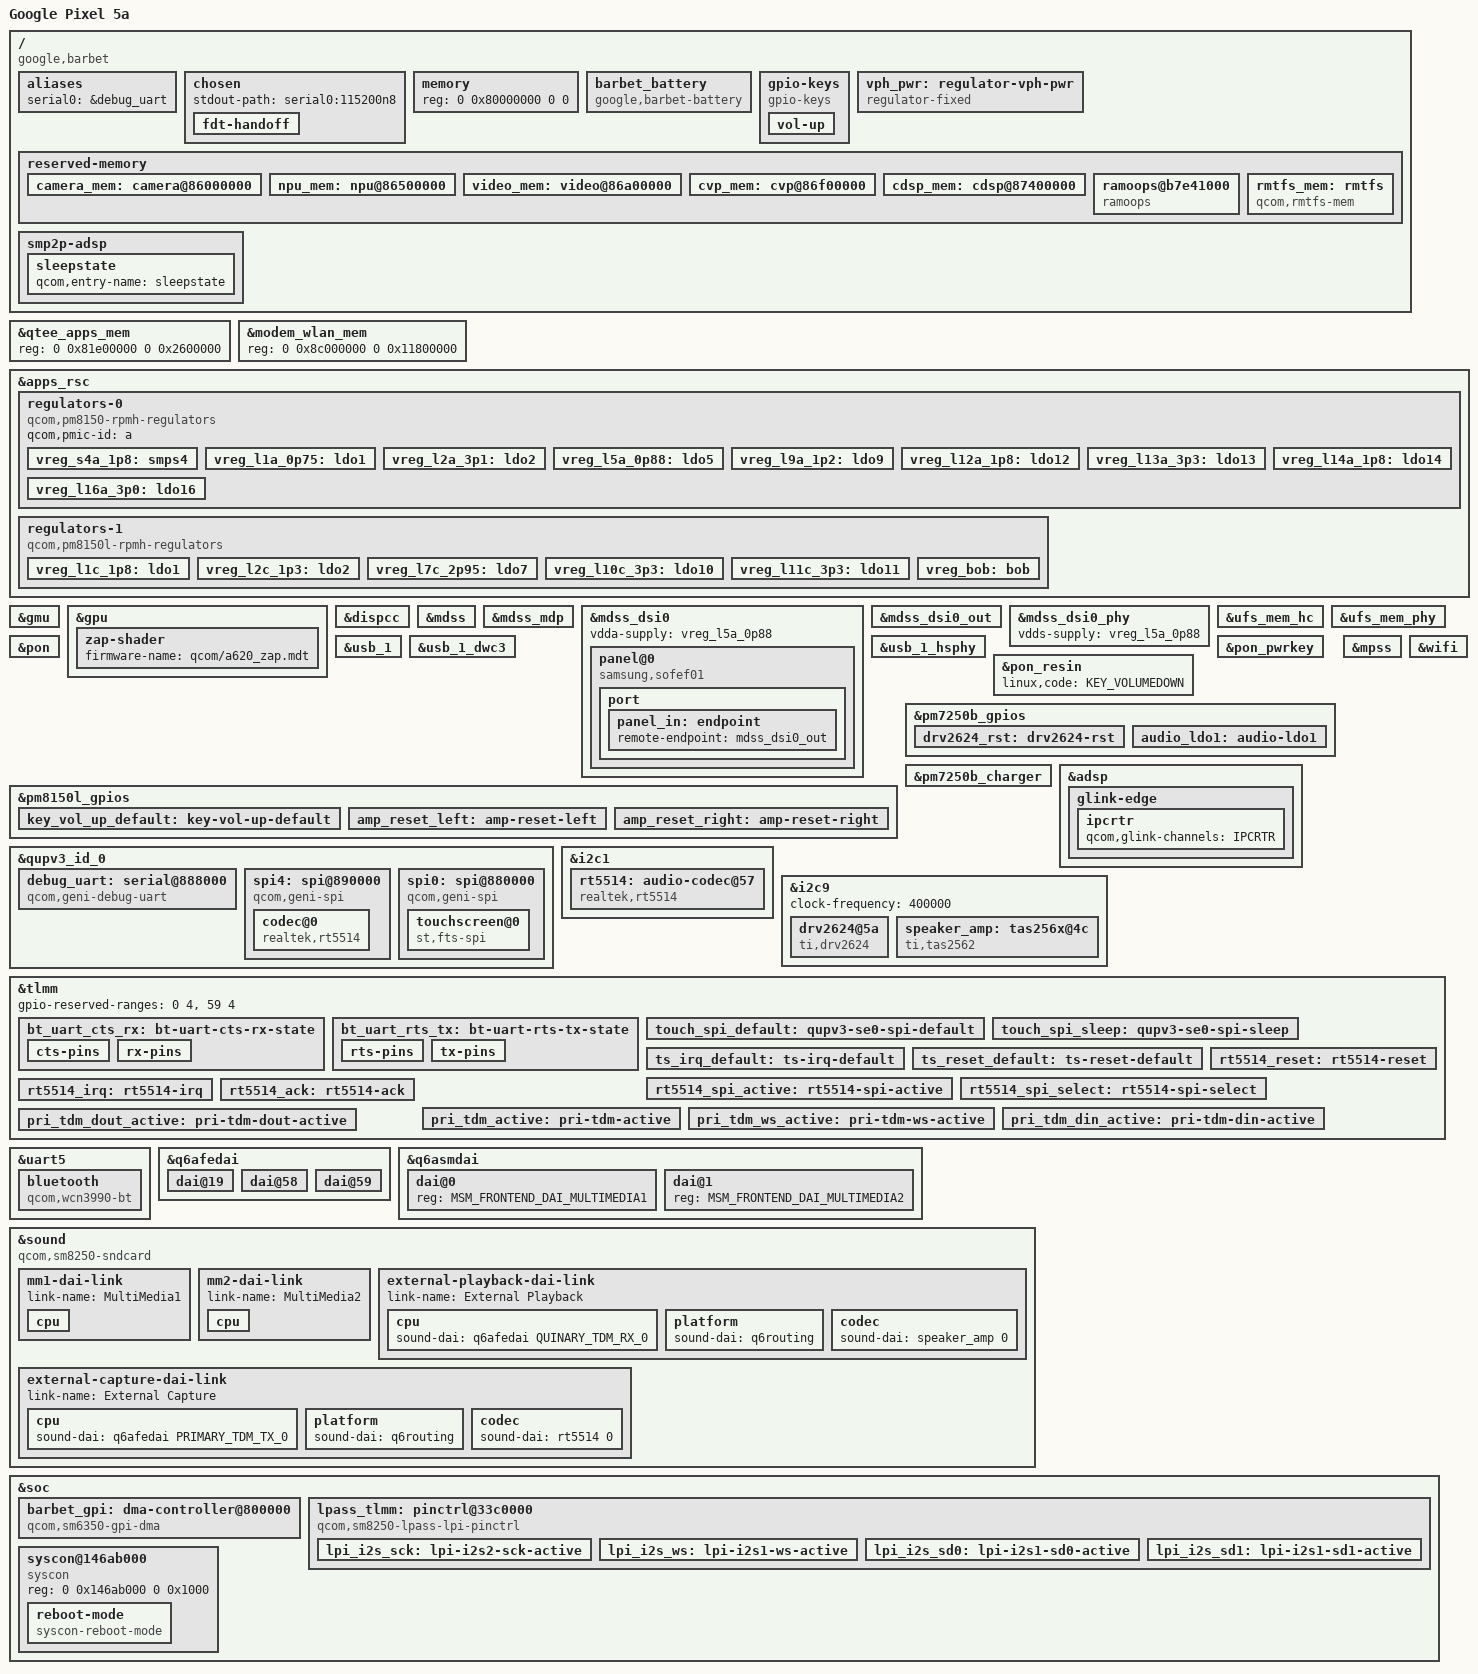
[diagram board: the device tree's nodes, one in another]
// SPDX-License-Identifier: BSD-3-Clause
/*
 * Google Pixel 5a (barbet).
 *
 * Family layout and regulator descriptions derive from the avicii-mainline
 * sm7250-oneplus-avicii.dts source (Sreeshankar K's SM7250 work).
 * Board wiring and reserved-memory sizes were checked against Google's
 * redbull kernel sources: lito-barbet.dtsi, lito-barbet-audio.dtsi and
 * lito-barbet-haptics.dtsi. The compiled bring-up tree is comparison evidence,
 * not an included or decompiled source tree.
 */

/dts-v1/;

#include <dt-bindings/gpio/gpio.h>
#include <dt-bindings/input/input.h>
#include <dt-bindings/pinctrl/qcom,pmic-gpio.h>
#include <dt-bindings/regulator/qcom,rpmh-regulator.h>
#include <dt-bindings/sound/qcom,q6asm.h>

#define PM7250B_SID 2
#define PM7250B_SID1 3

#include "sm7250.dtsi"
#include "pm8150.dtsi"
#include "pm8150l.dtsi"
#include "pm7250b.dtsi"

/* Replace the family defaults with Google's carveout addresses. */
/delete-node/ &camera_mem;
/delete-node/ &npu_mem;
/delete-node/ &video_mem;
/delete-node/ &cvp_mem;
/delete-node/ &cdsp_mem;

/ {
	model = "Google Pixel 5a";
	compatible = "google,barbet", "qcom,sm7250", "qcom,lito";
	chassis-type = "handset";
	qcom,msm-id = <0x190 0x10000 0x1b8 0x10000>;
	qcom,board-id = <0 0>;

	aliases {
		serial0 = &debug_uart;
	};

	chosen {
		stdout-path = "serial0:115200n8";

		/*
		 * Hand the bootloader's own Barbet tree to the kernel's
		 * matching one, and keep the initramfs the bootloader loaded.
		 */
		fdt-handoff {
			stock-compatible = "google,barbet-sm7250";
			stock-model = "Google Inc. MSM sm7250 v2 Barbet MP";
			keep-initrd;
		};
	};

	/*
	 * The Pixel bootloader patches /memory (without a unit address), so
	 * keep the stock node shape for it to fill in the real DRAM size.
	 */
	memory {
		device_type = "memory";
		reg = <0 0x80000000 0 0>;
	};

	barbet_battery {
		compatible = "google,barbet-battery";
		io-channels = <&pm7250b_adc 0x84>;
		voltage-min-microvolt = <3200000>;
		voltage-max-microvolt = <4350000>;
	};

	gpio-keys {
		compatible = "gpio-keys";
		label = "gpio-keys";
		pinctrl-names = "default";
		pinctrl-0 = <&key_vol_up_default>;

		vol-up {
			label = "Volume Up";
			gpios = <&pm8150l_gpios 5 GPIO_ACTIVE_LOW>;
			linux,code = <KEY_VOLUMEUP>;
			debounce-interval = <15>;
			wakeup-source;
		};
	};

	vph_pwr: regulator-vph-pwr {
		compatible = "regulator-fixed";
		regulator-name = "vph_pwr";
		regulator-min-microvolt = <4200000>;
		regulator-max-microvolt = <4200000>;
		regulator-always-on;
	};

	reserved-memory {
		camera_mem: camera@86000000 {
			reg = <0 0x86000000 0 0x500000>;
			no-map;
		};

		npu_mem: npu@86500000 {
			reg = <0 0x86500000 0 0x500000>;
			no-map;
		};

		video_mem: video@86a00000 {
			reg = <0 0x86a00000 0 0x500000>;
			no-map;
		};

		cvp_mem: cvp@86f00000 {
			reg = <0 0x86f00000 0 0x500000>;
			no-map;
		};

		cdsp_mem: cdsp@87400000 {
			reg = <0 0x87400000 0 0x1e00000>;
			no-map;
		};

		ramoops@b7e41000 {
			compatible = "ramoops";
			reg = <0 0xb7e41000 0 0x400000>;
			record-size = <0x20000>;
			console-size = <0x100000>;
			pmsg-size = <0x80000>;
			no-map;
		};

		rmtfs_mem: rmtfs {
			compatible = "qcom,rmtfs-mem";
			size = <0 0x280000>;
			alloc-ranges = <0 0xa4000000 0 0x10000000>;
			alignment = <0 0x400000>;
			no-map;
			qcom,client-id = <1>;
			qcom,vmid = <15>;
		};
	};

	smp2p-adsp {
		sleepstate {
			qcom,entry-name = "sleepstate";
			#qcom,smem-state-cells = <1>;
		};
	};
};

/* Barbet's firmware carveouts differ from the OnePlus memory map. */
&qtee_apps_mem {
	reg = <0 0x81e00000 0 0x2600000>;
};

&modem_wlan_mem {
	reg = <0 0x8c000000 0 0x11800000>;
};

&apps_rsc {
	regulators-0 {
		compatible = "qcom,pm8150-rpmh-regulators";
		qcom,pmic-id = "a";

		vreg_s4a_1p8: smps4 {
			regulator-name = "vreg_s4a_1p8";
			regulator-min-microvolt = <1800000>;
			regulator-max-microvolt = <1800000>;
			regulator-boot-on;
			regulator-always-on;
		};

		vreg_l1a_0p75: ldo1 {
			regulator-name = "vreg_l1a_0p75";
			regulator-min-microvolt = <752000>;
			regulator-max-microvolt = <752000>;
			regulator-initial-mode = <RPMH_REGULATOR_MODE_HPM>;
			regulator-boot-on;
			regulator-always-on;
		};

		vreg_l2a_3p1: ldo2 {
			regulator-name = "vreg_l2a_3p1";
			regulator-min-microvolt = <3072000>;
			regulator-max-microvolt = <3072000>;
			regulator-initial-mode = <RPMH_REGULATOR_MODE_HPM>;
			regulator-boot-on;
			regulator-always-on;
		};

		vreg_l5a_0p88: ldo5 {
			regulator-name = "vreg_l5a_0p88";
			regulator-min-microvolt = <880000>;
			regulator-max-microvolt = <880000>;
			regulator-initial-mode = <RPMH_REGULATOR_MODE_HPM>;
			regulator-boot-on;
			regulator-always-on;
		};

		vreg_l9a_1p2: ldo9 {
			regulator-name = "vreg_l9a_1p2";
			regulator-min-microvolt = <1200000>;
			regulator-max-microvolt = <1200000>;
			regulator-initial-mode = <RPMH_REGULATOR_MODE_HPM>;
			regulator-boot-on;
			regulator-always-on;
		};

		vreg_l12a_1p8: ldo12 {
			regulator-name = "vreg_l12a_1p8";
			regulator-min-microvolt = <1800000>;
			regulator-max-microvolt = <1800000>;
			regulator-initial-mode = <RPMH_REGULATOR_MODE_HPM>;
			regulator-boot-on;
			regulator-always-on;
		};

		vreg_l13a_3p3: ldo13 {
			regulator-name = "vreg_l13a_3p3";
			regulator-min-microvolt = <3304000>;
			regulator-max-microvolt = <3304000>;
			regulator-initial-mode = <RPMH_REGULATOR_MODE_HPM>;
			regulator-boot-on;
			regulator-always-on;
		};

		vreg_l14a_1p8: ldo14 {
			regulator-name = "vreg_l14a_1p8";
			regulator-min-microvolt = <1800000>;
			regulator-max-microvolt = <1800000>;
			regulator-initial-mode = <RPMH_REGULATOR_MODE_HPM>;
			regulator-boot-on;
			regulator-always-on;
		};

		vreg_l16a_3p0: ldo16 {
			regulator-name = "vreg_l16a_3p0";
			regulator-min-microvolt = <3000000>;
			regulator-max-microvolt = <3000000>;
			regulator-initial-mode = <RPMH_REGULATOR_MODE_HPM>;
			regulator-boot-on;
			regulator-always-on;
		};
	};

	regulators-1 {
		compatible = "qcom,pm8150l-rpmh-regulators";
		qcom,pmic-id = "c";
		vdd-bob-supply = <&vph_pwr>;

		vreg_l1c_1p8: ldo1 {
			regulator-name = "vreg_l1c_1p8";
			regulator-min-microvolt = <1800000>;
			regulator-max-microvolt = <1800000>;
			regulator-initial-mode = <RPMH_REGULATOR_MODE_HPM>;
			regulator-boot-on;
			regulator-always-on;
		};

		vreg_l2c_1p3: ldo2 {
			regulator-name = "vreg_l2c_1p3";
			regulator-min-microvolt = <1304000>;
			regulator-max-microvolt = <1304000>;
			regulator-initial-mode = <RPMH_REGULATOR_MODE_HPM>;
		};

		vreg_l7c_2p95: ldo7 {
			regulator-name = "vreg_l7c_2p95";
			regulator-min-microvolt = <2950000>;
			regulator-max-microvolt = <2960000>;
			regulator-initial-mode = <RPMH_REGULATOR_MODE_HPM>;
			regulator-boot-on;
			regulator-always-on;
		};

		vreg_l10c_3p3: ldo10 {
			regulator-name = "vreg_l10c_3p3";
			regulator-min-microvolt = <3312000>;
			regulator-max-microvolt = <3312000>;
			regulator-initial-mode = <RPMH_REGULATOR_MODE_HPM>;
		};

		vreg_l11c_3p3: ldo11 {
			regulator-name = "vreg_l11c_3p3";
			regulator-min-microvolt = <3312000>;
			regulator-max-microvolt = <3312000>;
			regulator-initial-mode = <RPMH_REGULATOR_MODE_HPM>;
		};

		vreg_bob: bob {
			regulator-name = "vreg_bob";
			regulator-min-microvolt = <3008000>;
			regulator-max-microvolt = <4000000>;
			regulator-initial-mode = <RPMH_REGULATOR_MODE_AUTO>;
			regulator-boot-on;
		};
	};
};

&gmu {
	status = "okay";
};

&gpu {
	status = "okay";
	zap-shader {
		firmware-name = "qcom/a620_zap.mdt";
	};
};

&dispcc {
	status = "okay";
};

&mdss {
	status = "okay";
};

&mdss_mdp {
	status = "okay";
};

&mdss_dsi0 {
	vdda-supply = <&vreg_l5a_0p88>;
	status = "okay";

	panel@0 {
		compatible = "samsung,sofef01";
		reg = <0>;
		vddio-supply = <&vreg_l1c_1p8>;
		vci-supply = <&vreg_l16a_3p0>;
		poc-supply = <&vreg_l16a_3p0>;
		reset-gpios = <&pm8150l_gpios 8 GPIO_ACTIVE_LOW>;

		port {
			panel_in: endpoint {
				remote-endpoint = <&mdss_dsi0_out>;
			};
		};
	};
};

&mdss_dsi0_out {
	remote-endpoint = <&panel_in>;
	data-lanes = <0 1 2 3>;
};

&mdss_dsi0_phy {
	vdds-supply = <&vreg_l5a_0p88>;
	status = "okay";
};

&ufs_mem_hc {
	vcc-supply = <&vreg_l7c_2p95>;
	vcc-max-microamp = <800000>;
	vccq2-supply = <&vreg_s4a_1p8>;
	vccq2-max-microamp = <800000>;
	status = "okay";
};

&ufs_mem_phy {
	vdda-phy-supply = <&vreg_l5a_0p88>;
	vdda-pll-supply = <&vreg_l9a_1p2>;
	status = "okay";
};

&usb_1 {
	status = "okay";
};

&usb_1_dwc3 {
	dr_mode = "peripheral";
	maximum-speed = "high-speed";
};

&usb_1_hsphy {
	vdda-pll-supply = <&vreg_l5a_0p88>;
	vdda18-supply = <&vreg_l12a_1p8>;
	vdda33-supply = <&vreg_l2a_3p1>;
	status = "okay";
};

&pon {
	mode-normal = <0>;
	mode-bootloader = <2>;
	mode-recovery = <1>;
};

&pon_pwrkey {
	status = "okay";
};

&pon_resin {
	linux,code = <KEY_VOLUMEDOWN>;
	status = "okay";
};

&pm8150l_gpios {
	key_vol_up_default: key-vol-up-default {
		pins = "gpio5";
		function = "normal";
		input-enable;
		bias-pull-up;
		power-source = <0>;
	};

	amp_reset_left: amp-reset-left {
		pins = "gpio11";
		function = "normal";
		power-source = <1>;
		qcom,drive-strength = <PMIC_GPIO_STRENGTH_MED>;
		bias-disable;
		output-high;
	};

	amp_reset_right: amp-reset-right {
		pins = "gpio10";
		function = "normal";
		power-source = <1>;
		qcom,drive-strength = <PMIC_GPIO_STRENGTH_MED>;
		bias-disable;
		output-high;
	};
};

&pm7250b_gpios {
	drv2624_rst: drv2624-rst {
		pins = "gpio1";
		output-low;
	};

	audio_ldo1: audio-ldo1 {
		pins = "gpio6";
		function = "normal";
		power-source = <1>;
		qcom,drive-strength = <PMIC_GPIO_STRENGTH_MED>;
		output-high;
	};
};

&pm7250b_charger {
	status = "okay";
};

&adsp {
	firmware-name = "qcom/sm7250/google/barbet/adsp.mdt";
	status = "okay";

	glink-edge {
		ipcrtr {
			qcom,glink-channels = "IPCRTR";
		};
	};
};

&mpss {
	firmware-name = "qcom/sm7250/google/barbet/modem.mdt";
	status = "okay";
};

&wifi {
	vdd-0.8-cx-mx-supply = <&vreg_l1a_0p75>;
	vdd-1.8-xo-supply = <&vreg_l14a_1p8>;
	vdd-1.3-rfa-supply = <&vreg_l2c_1p3>;
	vdd-3.3-ch0-supply = <&vreg_l10c_3p3>;
	vdd-3.3-ch1-supply = <&vreg_l11c_3p3>;
	firmware-name = "barbet";
	status = "okay";
};

&qupv3_id_0 {
	status = "okay";

	debug_uart: serial@888000 {
		compatible = "qcom,geni-debug-uart";
		reg = <0 0x888000 0 0x4000>;
		clock-names = "se";
		clocks = <&gcc GCC_QUPV3_WRAP0_S2_CLK>;
		interrupts = <GIC_SPI 603 IRQ_TYPE_LEVEL_HIGH>;
		pinctrl-names = "default";
		pinctrl-0 = <&qup_uart2_default>;
		interconnects = <&qup_virt MASTER_QUP_CORE_0 QCOM_ICC_TAG_ALWAYS
				 &qup_virt SLAVE_QUP_CORE_0 QCOM_ICC_TAG_ALWAYS>,
			       <&gem_noc MASTER_AMPSS_M0 QCOM_ICC_TAG_ACTIVE_ONLY
				 &config_noc SLAVE_QUP_0 QCOM_ICC_TAG_ACTIVE_ONLY>;
		interconnect-names = "qup-core", "qup-config";
		status = "okay";
	};

	spi4: spi@890000 {
		compatible = "qcom,geni-spi";
		reg = <0 0x890000 0 0x4000>;
		clock-names = "se";
		clocks = <&gcc GCC_QUPV3_WRAP0_S4_CLK>;
		interrupts = <GIC_SPI 605 IRQ_TYPE_LEVEL_HIGH>;
		#address-cells = <1>;
		#size-cells = <0>;
		dmas = <&barbet_gpi 0 4 QCOM_GPI_SPI>,
		       <&barbet_gpi 1 4 QCOM_GPI_SPI>;
		dma-names = "tx", "rx";
		pinctrl-names = "default";
		pinctrl-0 = <&rt5514_spi_active>, <&rt5514_spi_select>;
		interconnects = <&qup_virt MASTER_QUP_CORE_0 QCOM_ICC_TAG_ALWAYS
				 &qup_virt SLAVE_QUP_CORE_0 QCOM_ICC_TAG_ALWAYS>,
			       <&gem_noc MASTER_AMPSS_M0 QCOM_ICC_TAG_ACTIVE_ONLY
				 &config_noc SLAVE_QUP_0 QCOM_ICC_TAG_ACTIVE_ONLY>,
			       <&aggre2_noc MASTER_QUP_0 QCOM_ICC_TAG_ALWAYS
				 &mc_virt SLAVE_EBI_CH0 QCOM_ICC_TAG_ALWAYS>;
		interconnect-names = "qup-core", "qup-config", "qup-memory";

		codec@0 {
			compatible = "realtek,rt5514";
			reg = <0>;
			spi-max-frequency = <10000000>;
			spi-cpol;
			spi-cpha;
			interrupt-parent = <&tlmm>;
			interrupts = <65 IRQ_TYPE_NONE>, <11 IRQ_TYPE_NONE>;
			interrupt-names = "irq", "handshake-ack";
			irq-gpio = <&tlmm 65 GPIO_ACTIVE_HIGH>;
			handshake-gpio = <&tlmm 66 GPIO_ACTIVE_HIGH>;
			handshake-ack-gpio = <&tlmm 11 GPIO_ACTIVE_HIGH>;
			pinctrl-names = "default";
			pinctrl-0 = <&rt5514_irq>, <&rt5514_ack>;
		};
	};
};

/* SE0 uses SPI rather than the I2C personality in the family description. */
/delete-node/ &i2c0;

&qupv3_id_0 {
	spi0: spi@880000 {
		compatible = "qcom,geni-spi";
		reg = <0 0x880000 0 0x4000>;
		clock-names = "se";
		clocks = <&gcc GCC_QUPV3_WRAP0_S0_CLK>;
		interrupts = <GIC_SPI 601 IRQ_TYPE_LEVEL_HIGH>;
		#address-cells = <1>;
		#size-cells = <0>;
		interconnects = <&qup_virt MASTER_QUP_CORE_0 QCOM_ICC_TAG_ALWAYS
				 &qup_virt SLAVE_QUP_CORE_0 QCOM_ICC_TAG_ALWAYS>,
			       <&gem_noc MASTER_AMPSS_M0 QCOM_ICC_TAG_ACTIVE_ONLY
				 &config_noc SLAVE_QUP_0 QCOM_ICC_TAG_ACTIVE_ONLY>,
			       <&aggre2_noc MASTER_QUP_0 QCOM_ICC_TAG_ALWAYS
				 &mc_virt SLAVE_EBI_CH0 QCOM_ICC_TAG_ALWAYS>;
		interconnect-names = "qup-core", "qup-config", "qup-memory";
		pinctrl-names = "default", "sleep";
		pinctrl-0 = <&touch_spi_default>;
		pinctrl-1 = <&touch_spi_sleep>;
		status = "okay";

		touchscreen@0 {
			compatible = "st,fts-spi";
			reg = <0>;
			spi-max-frequency = <10000000>;
			interrupt-parent = <&tlmm>;
			interrupts = <9 IRQ_TYPE_LEVEL_LOW>;
			reset-gpios = <&tlmm 8 GPIO_ACTIVE_LOW>;
			ap2lpi-gpios = <&tlmm 35 GPIO_ACTIVE_HIGH>;
			lpi2ap-gpios = <&tlmm 5 GPIO_ACTIVE_HIGH>;
			vdd-supply = <&vreg_l13a_3p3>;
			pinctrl-names = "default";
			pinctrl-0 = <&ts_irq_default>, <&ts_reset_default>;
			touchscreen-size-x = <1080>;
			touchscreen-size-y = <2400>;
			st,max-coords = <1079 2399>;
			st,force-pi-cfg-ver-map = <0x300 0x306>;
			st,save-golden-ms-raw;
			status = "okay";
		};
	};
};

&i2c1 {
	status = "okay";

	rt5514: audio-codec@57 {
		compatible = "realtek,rt5514";
		reg = <0x57>;
		#sound-dai-cells = <1>;
		reset-gpio = <&tlmm 91 GPIO_ACTIVE_HIGH>;
		handshake-gpio = <&tlmm 66 GPIO_ACTIVE_HIGH>;
		pinctrl-names = "default";
		pinctrl-0 = <&audio_ldo1>, <&rt5514_reset>,
			    <&pri_tdm_active>, <&pri_tdm_ws_active>,
			    <&pri_tdm_din_active>, <&pri_tdm_dout_active>;
	};
};

&i2c9 {
	clock-frequency = <400000>;
	status = "okay";

	drv2624@5a {
		compatible = "ti,drv2624";
		reg = <0x5a>;
		pinctrl-names = "default";
		pinctrl-0 = <&drv2624_rst>;
		reset-gpio = <&pm7250b_gpios 1 GPIO_ACTIVE_HIGH>;
		ti,smart-loop = <1>;
		ti,actuator = <1>;
		ti,rated-voltage = /bits/ 8 <109>;
		ti,odclamp-voltage = /bits/ 8 <161>;
	};

	speaker_amp: tas256x@4c {
		compatible = "ti,tas2562";
		reg = <0x4c>;
		#sound-dai-cells = <1>;
		ti,left-channel = <0x4c>;
		ti,right-channel = <0x4d>;
		reset-gpios = <&pm8150l_gpios 10 GPIO_ACTIVE_HIGH>;
		shutdown-gpios = <&pm8150l_gpios 11 GPIO_ACTIVE_HIGH>;
		pinctrl-names = "default", "sleep";
		pinctrl-0 = <&lpi_i2s_sck>, <&lpi_i2s_ws>,
			    <&lpi_i2s_sd0>, <&lpi_i2s_sd1>,
			    <&amp_reset_left>, <&amp_reset_right>;
		pinctrl-1 = <&lpi_i2s_sck>, <&lpi_i2s_ws>,
			    <&lpi_i2s_sd0>, <&lpi_i2s_sd1>,
			    <&amp_reset_left>, <&amp_reset_right>;
	};
};

&tlmm {
	/* Secure-world peripherals: do not read their pin configuration. */
	gpio-reserved-ranges = <0 4>, <59 4>;

	bt_uart_cts_rx: bt-uart-cts-rx-state {
		cts-pins {
			pins = "gpio38";
			function = "qup05";
			drive-strength = <2>;
			bias-pull-down;
		};
		rx-pins {
			pins = "gpio41";
			function = "qup05";
			drive-strength = <2>;
			bias-pull-up;
		};
	};

	bt_uart_rts_tx: bt-uart-rts-tx-state {
		rts-pins {
			pins = "gpio39";
			function = "qup05";
			drive-strength = <2>;
			bias-pull-down;
		};
		tx-pins {
			pins = "gpio40";
			function = "qup05";
			drive-strength = <2>;
			bias-pull-up;
		};
	};

	touch_spi_default: qupv3-se0-spi-default {
		pins = "gpio42", "gpio43", "gpio44", "gpio45";
		function = "qup00";
		drive-strength = <6>;
		bias-disable;
	};

	touch_spi_sleep: qupv3-se0-spi-sleep {
		pins = "gpio42", "gpio43", "gpio44", "gpio45";
		function = "gpio";
		drive-strength = <2>;
		bias-pull-down;
	};

	ts_irq_default: ts-irq-default {
		pins = "gpio9";
		function = "gpio";
		bias-pull-up;
		input-enable;
	};

	ts_reset_default: ts-reset-default {
		pins = "gpio8";
		function = "gpio";
		drive-strength = <2>;
		bias-disable;
		output-low;
	};

	rt5514_reset: rt5514-reset {
		pins = "gpio91";
		function = "gpio";
		drive-strength = <2>;
		output-high;
	};

	rt5514_spi_active: rt5514-spi-active {
		pins = "gpio29", "gpio30", "gpio31", "gpio32";
		function = "qup04";
		drive-strength = <6>;
		bias-disable;
	};

	rt5514_spi_select: rt5514-spi-select {
		pins = "gpio66";
		function = "gpio";
		drive-strength = <2>;
		output-high;
	};

	rt5514_irq: rt5514-irq {
		pins = "gpio65";
		function = "gpio";
		drive-strength = <2>;
		bias-pull-down;
		input-enable;
	};

	rt5514_ack: rt5514-ack {
		pins = "gpio11";
		function = "gpio";
		drive-strength = <2>;
		bias-pull-down;
		input-enable;
	};

	pri_tdm_active: pri-tdm-active {
		pins = "gpio49";
		function = "pri_mi2s";
		drive-strength = <8>;
		bias-disable;
	};

	pri_tdm_ws_active: pri-tdm-ws-active {
		pins = "gpio50";
		function = "pri_mi2s_ws";
		drive-strength = <8>;
		bias-disable;
	};

	pri_tdm_din_active: pri-tdm-din-active {
		pins = "gpio51";
		function = "pri_mi2s";
		drive-strength = <8>;
		bias-disable;
	};

	pri_tdm_dout_active: pri-tdm-dout-active {
		pins = "gpio52";
		function = "pri_mi2s";
		drive-strength = <8>;
		bias-disable;
	};
};

/* Kept disabled until Bluetooth firmware loading is qualified separately. */
&uart5 {
	pinctrl-0 = <&bt_uart_cts_rx>, <&bt_uart_rts_tx>;
	pinctrl-1 = <&bt_uart_cts_rx>, <&bt_uart_rts_tx>;

	bluetooth {
		compatible = "qcom,wcn3990-bt";
		vddio-supply = <&vreg_s4a_1p8>;
		vddxo-supply = <&vreg_l14a_1p8>;
		vddrf-supply = <&vreg_l2c_1p3>;
		vddch0-supply = <&vreg_l10c_3p3>;
		swctrl-gpios = <&tlmm 73 GPIO_ACTIVE_HIGH>;
		max-speed = <3200000>;
	};
};

&q6afedai {
	dai@19 {
		reg = <PRIMARY_TDM_TX_0>;
		qcom,tdm-sync-mode = <0>;
		qcom,tdm-sync-src = <1>;
		qcom,tdm-data-out = <0>;
		qcom,tdm-invert-sync = <0>;
		qcom,tdm-data-delay = <1>;
		qcom,tdm-data-align = <0>;
	};

	dai@58 {
		reg = <QUINARY_TDM_RX_0>;
		qcom,tdm-sync-mode = <0>;
		qcom,tdm-sync-src = <1>;
		qcom,tdm-data-out = <0>;
		qcom,tdm-invert-sync = <1>;
		qcom,tdm-data-delay = <1>;
		qcom,tdm-data-align = <0>;
	};

	dai@59 {
		reg = <QUINARY_TDM_TX_0>;
		qcom,tdm-sync-mode = <0>;
		qcom,tdm-sync-src = <0>;
		qcom,tdm-data-out = <1>;
		qcom,tdm-invert-sync = <1>;
		qcom,tdm-data-delay = <1>;
		qcom,tdm-data-align = <0>;
	};
};

&q6asmdai {
	dai@0 {
		reg = <MSM_FRONTEND_DAI_MULTIMEDIA1>;
	};

	dai@1 {
		reg = <MSM_FRONTEND_DAI_MULTIMEDIA2>;
	};
};

&sound {
	compatible = "qcom,sm8250-sndcard";
	model = "barbet";
	clocks = <&q6afecc LPASS_HW_MACRO_VOTE 1>,
		 <&q6afecc LPASS_HW_DCODEC_VOTE 1>,
		 <&q6afecc LPASS_CLK_ID_PRI_TDM_IBIT 1>,
		 <&q6afecc LPASS_CLK_ID_QUIN_TDM_IBIT 1>;
	clock-names = "lpass_audio_hw_vote", "lpass_dcodec_hw_vote",
		      "lpass_pri_tdm_ibit", "lpass_quin_tdm_ibit";

	mm1-dai-link {
		link-name = "MultiMedia1";
		cpu {
			sound-dai = <&q6asmdai MSM_FRONTEND_DAI_MULTIMEDIA1>;
		};
	};

	mm2-dai-link {
		link-name = "MultiMedia2";
		cpu {
			sound-dai = <&q6asmdai MSM_FRONTEND_DAI_MULTIMEDIA2>;
		};
	};

	external-playback-dai-link {
		link-name = "External Playback";
		cpu {
			sound-dai = <&q6afedai QUINARY_TDM_RX_0>;
		};
		platform {
			sound-dai = <&q6routing>;
		};
		codec {
			sound-dai = <&speaker_amp 0>;
		};
	};

	external-capture-dai-link {
		link-name = "External Capture";
		cpu {
			sound-dai = <&q6afedai PRIMARY_TDM_TX_0>;
		};
		platform {
			sound-dai = <&q6routing>;
		};
		codec {
			sound-dai = <&rt5514 0>;
		};
	};
};

&soc {
	barbet_gpi: dma-controller@800000 {
		compatible = "qcom,sm6350-gpi-dma";
		reg = <0 0x800000 0 0x60000>;
		interrupts = <GIC_SPI 244 IRQ_TYPE_LEVEL_HIGH>,
			     <GIC_SPI 245 IRQ_TYPE_LEVEL_HIGH>,
			     <GIC_SPI 246 IRQ_TYPE_LEVEL_HIGH>,
			     <GIC_SPI 247 IRQ_TYPE_LEVEL_HIGH>,
			     <GIC_SPI 248 IRQ_TYPE_LEVEL_HIGH>,
			     <GIC_SPI 249 IRQ_TYPE_LEVEL_HIGH>,
			     <GIC_SPI 250 IRQ_TYPE_LEVEL_HIGH>,
			     <GIC_SPI 251 IRQ_TYPE_LEVEL_HIGH>,
			     <GIC_SPI 252 IRQ_TYPE_LEVEL_HIGH>,
			     <GIC_SPI 253 IRQ_TYPE_LEVEL_HIGH>;
		dma-channels = <10>;
		dma-channel-mask = <0x1f>;
		iommus = <&apps_smmu 0x4f6 0>;
		#dma-cells = <3>;
	};

	lpass_tlmm: pinctrl@33c0000 {
		compatible = "qcom,sm8250-lpass-lpi-pinctrl";
		reg = <0 0x33c0000 0 0x20000>, <0 0x3550000 0 0x10000>;
		gpio-controller;
		#gpio-cells = <2>;
		gpio-ranges = <&lpass_tlmm 0 0 14>;
		clocks = <&q6afecc LPASS_HW_MACRO_VOTE 1>,
			 <&q6afecc LPASS_HW_DCODEC_VOTE 1>;
		clock-names = "core", "audio";

		lpi_i2s_sck: lpi-i2s2-sck-active {
			pins = "gpio6";
			function = "i2s1_clk";
			drive-strength = <8>;
			bias-disable;
			output-high;
		};
		lpi_i2s_ws: lpi-i2s1-ws-active {
			pins = "gpio7";
			function = "i2s1_ws";
			drive-strength = <8>;
			bias-disable;
			output-high;
		};
		lpi_i2s_sd0: lpi-i2s1-sd0-active {
			pins = "gpio8";
			function = "i2s1_data";
			drive-strength = <8>;
			bias-disable;
			output-high;
		};
		lpi_i2s_sd1: lpi-i2s1-sd1-active {
			pins = "gpio9";
			function = "i2s1_data";
			drive-strength = <8>;
			bias-disable;
			output-high;
		};
	};

	syscon@146ab000 {
		compatible = "syscon", "simple-mfd";
		reg = <0 0x146ab000 0 0x1000>;
		reboot-mode {
			compatible = "syscon-reboot-mode";
			offset = <0x65c>;
			mode-normal = <0x77665501>;
			mode-bootloader = <0x77665500>;
			mode-recovery = <0x77665502>;
		};
	};
};
